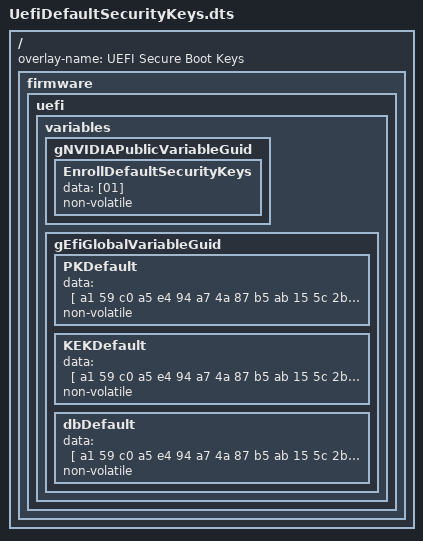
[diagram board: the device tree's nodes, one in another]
/** @file
*
*  Copyright (c) 2023, NVIDIA CORPORATION & AFFILIATES. All rights reserved.
*
*  SPDX-License-Identifier: BSD-2-Clause-Patent
*
**/
/dts-v1/;
/plugin/;
/ {
    overlay-name = "UEFI Secure Boot Keys";
    fragment@0 {
        target-path = "/";
        board_config {
            sw-modules = "uefi";
        };
        __overlay__ {
            firmware {
                uefi {
                    variables {
                        gNVIDIAPublicVariableGuid {
                            EnrollDefaultSecurityKeys {
                                data = [01];
                                non-volatile;
                            };
                        };
                        gEfiGlobalVariableGuid {
                            PKDefault {
                                data = [
 a1 59 c0 a5 e4 94 a7 4a 87 b5 ab 15 5c 2b f0 72
 1c 04 00 00 00 00 00 00 00 04 00 00 d3 23 47 68
 21 bc c0 4e be cd 2b 6a da 29 dd c1 30 82 03 ec
 30 82 02 d4 a0 03 02 01 02 02 09 00 c0 91 c5 e2
 b7 66 c0 f8 30 0d 06 09 2a 86 48 86 f7 0d 01 01
 0b 05 00 30 81 82 31 0b 30 09 06 03 55 04 06 13
 02 43 4e 31 0b 30 09 06 03 55 04 08 0c 02 53 48
 31 0b 30 09 06 03 55 04 07 0c 02 53 48 31 12 30
 10 06 03 55 04 0a 0c 09 54 69 61 6e 6f 43 6f 72
 65 31 0e 30 0c 06 03 55 04 0b 0c 05 45 44 4b 49
 49 31 11 30 0f 06 03 55 04 03 0c 08 54 65 73 74
 52 6f 6f 74 31 22 30 20 06 09 2a 86 48 86 f7 0d
 01 09 01 16 13 65 64 6b 69 69 40 74 69 61 6e 6f
 63 6f 72 65 2e 6f 72 67 30 1e 17 0d 31 37 30 34
 31 30 30 38 32 37 34 30 5a 17 0d 31 37 30 35 31
 30 30 38 32 37 34 30 5a 30 81 82 31 0b 30 09 06
 03 55 04 06 13 02 43 4e 31 0b 30 09 06 03 55 04
 08 0c 02 53 48 31 0b 30 09 06 03 55 04 07 0c 02
 53 48 31 12 30 10 06 03 55 04 0a 0c 09 54 69 61
 6e 6f 43 6f 72 65 31 0e 30 0c 06 03 55 04 0b 0c
 05 45 44 4b 49 49 31 11 30 0f 06 03 55 04 03 0c
 08 54 65 73 74 52 6f 6f 74 31 22 30 20 06 09 2a
 86 48 86 f7 0d 01 09 01 16 13 65 64 6b 69 69 40
 74 69 61 6e 6f 63 6f 72 65 2e 6f 72 67 30 82 01
 22 30 0d 06 09 2a 86 48 86 f7 0d 01 01 01 05 00
 03 82 01 0f 00 30 82 01 0a 02 82 01 01 00 b9 29
 29 6c 60 0c d7 23 f6 7d ee f0 62 ff d9 c9 aa 55
 8c 81 95 56 3f b7 56 53 b0 c2 82 12 c5 3b 75 23
 b9 4d d6 c4 55 73 f3 aa 95 a8 1b f3 93 7e 9e 40
 e4 1d 22 9c 93 07 0b d7 aa 5b d7 e4 1a 21 84 d7
 63 59 03 50 1f f5 14 55 93 91 9b f5 52 b0 bf 0e
 5c 68 3b 59 52 98 96 56 e1 ab c4 43 bb 05 57 78
 45 01 9f 58 15 53 0e 11 94 2f 0e f1 a6 19 a2 6e
 86 39 2b 33 8d c7 c5 eb ee 1e 33 d3 32 94 c1 59
 c4 0c 97 0b 12 48 5f 33 f6 60 74 7d 57 c2 13 2d
 7d a9 87 a3 35 ea 91 83 3f 67 7a 92 1f 01 53 9f
 62 5f 99 12 fd 73 1b 2d 9e 2b 6c 34 49 af 4f 07
 8f c0 e9 6b 9e 5f 79 35 da 2a 5c 88 ee f6 48 61
 da 96 e3 48 46 a0 94 1c 9d f6 5c 87 0e ef 74 09
 91 0d 3d 5a e7 c5 4c 8a 7a ac a1 85 b6 67 44 17
 55 52 3a e8 11 4d 58 a2 93 00 62 ea 7b 80 ed cf
 bd df 75 80 4b b9 65 63 ad 0b 4d 74 fa 59 02 03
 01 00 01 a3 63 30 61 30 1d 06 03 55 1d 0e 04 16
 04 14 16 aa d6 8e 1b 2d 43 f3 2d b0 24 ad 36 65
 3f b2 fa b1 2c ed 30 1f 06 03 55 1d 23 04 18 30
 16 80 14 16 aa d6 8e 1b 2d 43 f3 2d b0 24 ad 36
 65 3f b2 fa b1 2c ed 30 0f 06 03 55 1d 13 01 01
 ff 04 05 30 03 01 01 ff 30 0e 06 03 55 1d 0f 01
 01 ff 04 04 03 02 01 86 30 0d 06 09 2a 86 48 86
 f7 0d 01 01 0b 05 00 03 82 01 01 00 95 de df a4
 14 db 92 22 78 1a bd 31 9d 1e d7 2f 0a 10 11 5d
 74 61 e8 30 c4 f3 15 e9 30 54 f4 bb 0c 04 78 13
 5d 2c dd 8c 92 90 d1 9c d0 d0 18 a3 a3 fc 8c 28
 5a d4 91 4d 08 c3 f6 1a c8 dd a6 08 58 e2 15 95
 fb 2d 2d 8a b1 30 80 bd 9a b6 e1 2c 20 3e dd c4
 c7 55 65 cf 28 17 f4 ee da be 77 70 d5 52 d6 15
 7a fb ad af fd d5 45 90 5a e6 31 42 d7 84 b3 49
 56 6a d3 47 f3 bf 68 60 8b 0f e2 af f4 e3 ec 12
 b9 e2 3a 16 11 4e 4d 73 79 af 47 85 4c 76 26 9e
 8b 32 c0 8e c2 dc 27 a6 ef ac 93 9e a1 5e cf 34
 45 e0 2a c7 9d 4d d7 d7 37 72 97 f8 58 f9 b6 35
 48 f1 d1 0a 72 7f fd 4d 7c e9 cc d8 48 1b 49 52
 53 de 51 01 53 35 bc 90 cd 8c 8a cc 43 20 a7 45
 ff 2b 55 b0 8b 2d ff 55 15 4b 84 d0 c3 d3 90 9c
 94 4b 55 d5 62 ea 22 ab 62 68 dd 53 c6 dc a5 dd
 9a 2d 8e 79 7c 2e 9c e4 66 80 8c 1d
                                ];
                                non-volatile;
                            };
                            KEKDefault {
                                data = [
 a1 59 c0 a5 e4 94 a7 4a 87 b5 ab 15 5c 2b f0 72
 1c 04 00 00 00 00 00 00 00 04 00 00 48 ed ac b6
 b2 6b 0a 47 9d ac e5 ea e4 b2 0e 6c 30 82 03 ec
 30 82 02 d4 a0 03 02 01 02 02 09 00 c0 91 c5 e2
 b7 66 c0 f8 30 0d 06 09 2a 86 48 86 f7 0d 01 01
 0b 05 00 30 81 82 31 0b 30 09 06 03 55 04 06 13
 02 43 4e 31 0b 30 09 06 03 55 04 08 0c 02 53 48
 31 0b 30 09 06 03 55 04 07 0c 02 53 48 31 12 30
 10 06 03 55 04 0a 0c 09 54 69 61 6e 6f 43 6f 72
 65 31 0e 30 0c 06 03 55 04 0b 0c 05 45 44 4b 49
 49 31 11 30 0f 06 03 55 04 03 0c 08 54 65 73 74
 52 6f 6f 74 31 22 30 20 06 09 2a 86 48 86 f7 0d
 01 09 01 16 13 65 64 6b 69 69 40 74 69 61 6e 6f
 63 6f 72 65 2e 6f 72 67 30 1e 17 0d 31 37 30 34
 31 30 30 38 32 37 34 30 5a 17 0d 31 37 30 35 31
 30 30 38 32 37 34 30 5a 30 81 82 31 0b 30 09 06
 03 55 04 06 13 02 43 4e 31 0b 30 09 06 03 55 04
 08 0c 02 53 48 31 0b 30 09 06 03 55 04 07 0c 02
 53 48 31 12 30 10 06 03 55 04 0a 0c 09 54 69 61
 6e 6f 43 6f 72 65 31 0e 30 0c 06 03 55 04 0b 0c
 05 45 44 4b 49 49 31 11 30 0f 06 03 55 04 03 0c
 08 54 65 73 74 52 6f 6f 74 31 22 30 20 06 09 2a
 86 48 86 f7 0d 01 09 01 16 13 65 64 6b 69 69 40
 74 69 61 6e 6f 63 6f 72 65 2e 6f 72 67 30 82 01
 22 30 0d 06 09 2a 86 48 86 f7 0d 01 01 01 05 00
 03 82 01 0f 00 30 82 01 0a 02 82 01 01 00 b9 29
 29 6c 60 0c d7 23 f6 7d ee f0 62 ff d9 c9 aa 55
 8c 81 95 56 3f b7 56 53 b0 c2 82 12 c5 3b 75 23
 b9 4d d6 c4 55 73 f3 aa 95 a8 1b f3 93 7e 9e 40
 e4 1d 22 9c 93 07 0b d7 aa 5b d7 e4 1a 21 84 d7
 63 59 03 50 1f f5 14 55 93 91 9b f5 52 b0 bf 0e
 5c 68 3b 59 52 98 96 56 e1 ab c4 43 bb 05 57 78
 45 01 9f 58 15 53 0e 11 94 2f 0e f1 a6 19 a2 6e
 86 39 2b 33 8d c7 c5 eb ee 1e 33 d3 32 94 c1 59
 c4 0c 97 0b 12 48 5f 33 f6 60 74 7d 57 c2 13 2d
 7d a9 87 a3 35 ea 91 83 3f 67 7a 92 1f 01 53 9f
 62 5f 99 12 fd 73 1b 2d 9e 2b 6c 34 49 af 4f 07
 8f c0 e9 6b 9e 5f 79 35 da 2a 5c 88 ee f6 48 61
 da 96 e3 48 46 a0 94 1c 9d f6 5c 87 0e ef 74 09
 91 0d 3d 5a e7 c5 4c 8a 7a ac a1 85 b6 67 44 17
 55 52 3a e8 11 4d 58 a2 93 00 62 ea 7b 80 ed cf
 bd df 75 80 4b b9 65 63 ad 0b 4d 74 fa 59 02 03
 01 00 01 a3 63 30 61 30 1d 06 03 55 1d 0e 04 16
 04 14 16 aa d6 8e 1b 2d 43 f3 2d b0 24 ad 36 65
 3f b2 fa b1 2c ed 30 1f 06 03 55 1d 23 04 18 30
 16 80 14 16 aa d6 8e 1b 2d 43 f3 2d b0 24 ad 36
 65 3f b2 fa b1 2c ed 30 0f 06 03 55 1d 13 01 01
 ff 04 05 30 03 01 01 ff 30 0e 06 03 55 1d 0f 01
 01 ff 04 04 03 02 01 86 30 0d 06 09 2a 86 48 86
 f7 0d 01 01 0b 05 00 03 82 01 01 00 95 de df a4
 14 db 92 22 78 1a bd 31 9d 1e d7 2f 0a 10 11 5d
 74 61 e8 30 c4 f3 15 e9 30 54 f4 bb 0c 04 78 13
 5d 2c dd 8c 92 90 d1 9c d0 d0 18 a3 a3 fc 8c 28
 5a d4 91 4d 08 c3 f6 1a c8 dd a6 08 58 e2 15 95
 fb 2d 2d 8a b1 30 80 bd 9a b6 e1 2c 20 3e dd c4
 c7 55 65 cf 28 17 f4 ee da be 77 70 d5 52 d6 15
 7a fb ad af fd d5 45 90 5a e6 31 42 d7 84 b3 49
 56 6a d3 47 f3 bf 68 60 8b 0f e2 af f4 e3 ec 12
 b9 e2 3a 16 11 4e 4d 73 79 af 47 85 4c 76 26 9e
 8b 32 c0 8e c2 dc 27 a6 ef ac 93 9e a1 5e cf 34
 45 e0 2a c7 9d 4d d7 d7 37 72 97 f8 58 f9 b6 35
 48 f1 d1 0a 72 7f fd 4d 7c e9 cc d8 48 1b 49 52
 53 de 51 01 53 35 bc 90 cd 8c 8a cc 43 20 a7 45
 ff 2b 55 b0 8b 2d ff 55 15 4b 84 d0 c3 d3 90 9c
 94 4b 55 d5 62 ea 22 ab 62 68 dd 53 c6 dc a5 dd
 9a 2d 8e 79 7c 2e 9c e4 66 80 8c 1d
                                ];
                                non-volatile;
                            };
                            dbDefault {
                                data = [
 a1 59 c0 a5 e4 94 a7 4a 87 b5 ab 15 5c 2b f0 72
 06 04 00 00 00 00 00 00 ea 03 00 00 3f 8a ba 14
 a1 2e c0 4e 96 76 91 15 52 88 30 79 30 82 03 d6
 30 82 02 be a0 03 02 01 02 02 02 10 02 30 0d 06
 09 2a 86 48 86 f7 0d 01 01 0b 05 00 30 81 82 31
 0b 30 09 06 03 55 04 06 13 02 43 4e 31 0b 30 09
 06 03 55 04 08 0c 02 53 48 31 0b 30 09 06 03 55
 04 07 0c 02 53 48 31 12 30 10 06 03 55 04 0a 0c
 09 54 69 61 6e 6f 43 6f 72 65 31 0e 30 0c 06 03
 55 04 0b 0c 05 45 44 4b 49 49 31 11 30 0f 06 03
 55 04 03 0c 08 54 65 73 74 52 6f 6f 74 31 22 30
 20 06 09 2a 86 48 86 f7 0d 01 09 01 16 13 65 64
 6b 69 69 40 74 69 61 6e 6f 63 6f 72 65 2e 6f 72
 67 30 1e 17 0d 31 37 30 34 31 30 30 38 33 33 34
 35 5a 17 0d 31 38 30 34 31 30 30 38 33 33 34 35
 5a 30 74 31 0b 30 09 06 03 55 04 06 13 02 43 4e
 31 0b 30 09 06 03 55 04 08 0c 02 53 48 31 12 30
 10 06 03 55 04 0a 0c 09 54 69 61 6e 6f 43 6f 72
 65 31 0e 30 0c 06 03 55 04 0b 0c 05 45 44 4b 49
 49 31 10 30 0e 06 03 55 04 03 0c 07 54 65 73 74
 53 75 62 31 22 30 20 06 09 2a 86 48 86 f7 0d 01
 09 01 16 13 65 64 6b 69 69 40 74 69 61 6e 6f 63
 6f 72 65 2e 6f 72 67 30 82 01 22 30 0d 06 09 2a
 86 48 86 f7 0d 01 01 01 05 00 03 82 01 0f 00 30
 82 01 0a 02 82 01 01 00 c5 3a af 16 34 9a 14 61
 74 8c 39 1a 04 1f 7b 95 d3 40 b7 ea 26 a7 7b 8d
 76 d3 86 1b 7c 07 17 d2 56 72 36 13 b4 6c 75 b7
 bf d1 35 d1 31 d5 9a 07 c1 62 4e aa 3d bd d8 40
 8b 48 9a c5 46 c4 c3 10 2c d4 82 d9 6d f4 c3 de
 85 fa 34 1d d1 74 7a 5f 16 34 59 2b 2b 03 61 46
 62 d7 88 62 59 4d d8 55 00 52 54 e1 15 5e a9 ec
 d6 e8 51 fd ef 8e 68 5f d2 40 d2 61 ef 2c 1d 5b
 a7 6e 14 4c 12 bc 60 81 8e 66 c9 84 51 c2 89 51
 fc e5 7f 86 9a 78 a4 c1 f7 0f a9 a5 97 60 dd 6f
 c8 a0 fd ea 07 2f 01 36 0a e8 bd 0e dc 48 2e 85
 22 7b bb db 68 78 eb cd 6a 54 07 f7 81 a5 52 8f
 f3 5c 09 1e 76 a3 d1 91 8f ee 86 2c 85 49 99 96
 4f 5f 5b 0d 08 ae d8 20 e8 e3 67 70 c6 ec 0e 0e
 bd bf 3c f6 db e4 45 d5 7a bb 9f d1 3b 18 89 fc
 63 ac c2 30 b8 fa bb 8a 24 63 4e 79 58 78 72 ab
 27 36 3d bb 4f 47 d6 ef 02 03 01 00 01 a3 63 30
 61 30 1d 06 03 55 1d 0e 04 16 04 14 d6 9d 66 d6
 49 7c fa 20 8d 5d 75 69 2a 41 0a 7a 03 5a a5 eb
 30 1f 06 03 55 1d 23 04 18 30 16 80 14 16 aa d6
 8e 1b 2d 43 f3 2d b0 24 ad 36 65 3f b2 fa b1 2c
 ed 30 0f 06 03 55 1d 13 01 01 ff 04 05 30 03 01
 01 ff 30 0e 06 03 55 1d 0f 01 01 ff 04 04 03 02
 01 86 30 0d 06 09 2a 86 48 86 f7 0d 01 01 0b 05
 00 03 82 01 01 00 83 3c ae b2 fc 99 3d 33 b3 da
 ca 26 83 8c a9 ae f8 bb ad 05 37 97 a5 f8 0d 2b
 4e 3e e5 b7 12 68 f8 64 d4 bd ff 65 7d 57 98 61
 cd 47 10 a5 6a bd 66 89 74 ce 5e 28 29 39 67 c9
 1f 54 ec 78 76 b1 dd 04 91 63 b6 8c 2f 86 59 1f
 c4 2b a1 4a 8c a8 5b f6 8a 92 f0 83 bb 92 92 5c
 b1 1c 18 95 3d d6 be 6d 79 9d 4f 7b 92 1f 68 f5
 1f cd f4 37 2d 1e e3 f6 eb f2 8a a4 8d a1 c5 db
 0c 3a 59 01 dc be a9 c1 0b 04 ba e8 02 a9 85 cd
 d7 48 0d f6 60 30 2b 05 ba e0 c7 d8 9f 23 14 37
 04 0a a7 bc b6 c8 25 31 e4 9a 41 a5 83 c2 ee 89
 d3 fa a5 7c ae a6 14 22 a4 5f 73 03 f2 7b 3c 51
 f7 76 2a 0a cf ee 71 35 1c bc ff 3f 9b d5 b1 33
 e0 b6 fc 2a c8 ab 84 89 cd fa 1c ee 12 8c 07 ba
 93 46 50 b3 3f 73 05 be 67 58 60 90 05 2c d3 b6
 19 7c a4 f0 6e ee d4 f2 0e f5 02 79 5f 2c 28 83
 1e 83 c6 92 ba 7c
                                ];
                                non-volatile;
                            };
                        };
                    };
                };
            };
        };
    };
};
